VERSION ""

NS_ :

BS_:

BU_:

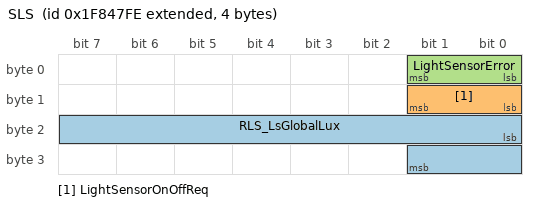
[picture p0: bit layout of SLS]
BO_ 2180532222 SLS: 4 Vector__XXX
 SG_ RLS_LsGlobalLux : 16|10@1+ (25,0) [0|25000] "" Vector__XXX
 SG_ LightSensorOnOffReq : 8|2@1+ (1,0) [0|0] "" Vector__XXX
 SG_ LightSensorError : 0|2@1+ (1,0) [0|3] "" Vector__XXX

CM_ "$File: //depot/auto/dbc/Software_Modules/Exterior_Lights/Light_Sensor/0.1.4.0/LightSens.dbc $
$Change: 216531 $
$DateTime: 2024/09/05 11:37:36 $
$Revision: #2 $";
CM_ BO_ 2180532222 "Control signals from light sensor";
CM_ SG_ 2180532222 RLS_LsGlobalLux "Raw lux value provided by the RLS driver";
BA_DEF_  "BusType" STRING ;
BA_DEF_  "DBName" STRING ;
BA_DEF_  "DatabaseVersion" STRING ;
BA_DEF_ BO_  "GenMsgCycleTime" INT 0 3600000;
BA_DEF_ BO_  "GenMsgDelayTime" INT 0 1000;
BA_DEF_ BO_  "GenMsgILSupport" ENUM  "No","Yes";
BA_DEF_ BO_  "GenMsgRequestable" INT 0 1;
BA_DEF_ BO_  "GenMsgSendType" ENUM  "cyclic","NotUsed","NotUsed","NotUsed","NotUsed","NotUsed","NotUsed","IfActive","noMsgSendType";
BA_DEF_ SG_  "GenSigEVName" STRING ;
BA_DEF_ SG_  "GenSigILSupport" ENUM  "No","Yes";
BA_DEF_ SG_  "GenSigSendType" ENUM  "Cyclic","OnWrite","OnWriteWithRepetition","OnChange","OnChangeWithRepetition","IfActive","IfActiveWithRepetition","NoSigSendType";
BA_DEF_ BU_  "NmStationAddress" INT 0 255;
BA_DEF_  "ProtocolType" STRING ;
BA_DEF_  "SAE_J1939_21_SpecVersion" STRING ;
BA_DEF_  "SAE_J1939_71_SpecVersion" STRING ;
BA_DEF_  "SAE_J1939_73_SpecVersion" STRING ;
BA_DEF_  "SAE_J1939_75_SpecVersion" STRING ;
BA_DEF_  "SAE_J1939_81_SpecVersion" STRING ;
BA_DEF_  "SAE_J1939_DA_SpecVersion" STRING ;
BA_DEF_ BO_  "SendOnChange" ENUM  "No","Yes";
BA_DEF_ SG_  "SigType" ENUM  "Default","Range","RangeSigned","ASCII","Discrete","Control","ReferencePGN","DTC","StringDelimiter","StringLength","StringLengthControl","MessageCounter","MessageChecksum";
BA_DEF_ BO_  "VFrameFormat" ENUM  "StandardCAN","ExtendedCAN","reserved","J1939PG","reserved","reserved","reserved","reserved","reserved","reserved","reserved","reserved","reserved","reserved","StandardCAN_FD","ExtendedCAN_FD";
BA_DEF_ BO_  "Producer" STRING ;
BA_DEF_DEF_  "BusType" "";
BA_DEF_DEF_  "DBName" "";
BA_DEF_DEF_  "DatabaseVersion" "";
BA_DEF_DEF_  "GenMsgCycleTime" 0;
BA_DEF_DEF_  "GenMsgDelayTime" 0;
BA_DEF_DEF_  "GenMsgILSupport" "Yes";
BA_DEF_DEF_  "GenMsgRequestable" 1;
BA_DEF_DEF_  "GenMsgSendType" "noMsgSendType";
BA_DEF_DEF_  "GenSigEVName" "Env@Nodename_@Signame";
BA_DEF_DEF_  "GenSigILSupport" "Yes";
BA_DEF_DEF_  "GenSigSendType" "NoSigSendType";
BA_DEF_DEF_  "NmStationAddress" 254;
BA_DEF_DEF_  "ProtocolType" "";
BA_DEF_DEF_  "SAE_J1939_21_SpecVersion" "";
BA_DEF_DEF_  "SAE_J1939_71_SpecVersion" "";
BA_DEF_DEF_  "SAE_J1939_73_SpecVersion" "";
BA_DEF_DEF_  "SAE_J1939_75_SpecVersion" "";
BA_DEF_DEF_  "SAE_J1939_81_SpecVersion" "";
BA_DEF_DEF_  "SAE_J1939_DA_SpecVersion" "";
BA_DEF_DEF_  "SendOnChange" "No";
BA_DEF_DEF_  "SigType" "Default";
BA_DEF_DEF_  "VFrameFormat" "J1939PG";
BA_DEF_DEF_  "Producer" "";
BA_ "SAE_J1939_DA_SpecVersion" "2015-01";
BA_ "SAE_J1939_81_SpecVersion" "2012-05";
BA_ "SAE_J1939_75_SpecVersion" "2012-05";
BA_ "SAE_J1939_73_SpecVersion" "2012-10";
BA_ "SAE_J1939_71_SpecVersion" "2012-10";
BA_ "SAE_J1939_21_SpecVersion" "2006-10";
BA_ "ProtocolType" "J1939";
BA_ "DatabaseVersion" "1.0";
BA_ "BusType" "CAN";
BA_ "DBName" "UIRSTRTCTRL";
BA_ "Producer" BO_ 2180532222 "WAWS";
BA_ "GenMsgDelayTime" BO_ 2180532222 100;
BA_ "SendOnChange" BO_ 2180532222 1;
BA_ "GenMsgSendType" BO_ 2180532222 0;
BA_ "GenMsgCycleTime" BO_ 2180532222 1000;
VAL_ 2180532222 LightSensorOnOffReq 3 "Not Available" 2 "Reserved" 1 "TurnOn" 0 "TurnOff" ;
VAL_ 2180532222 LightSensorError 3 "Not Available" 2 "Reserved" 1 "Erroneous" 0 "NoErrors" ;
